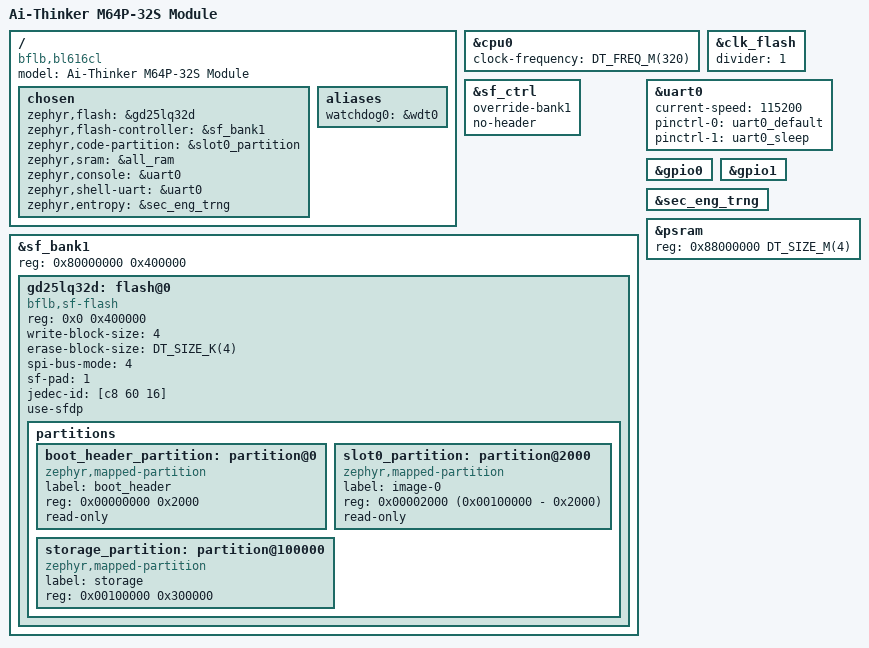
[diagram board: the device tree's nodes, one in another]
/*
 * Copyright (c) 2026 MASSDRIVER EI (massdriver.space)
 *
 * SPDX-License-Identifier: Apache-2.0
 */

#include <bflb/bl616cl.dtsi>
#include "ai_m64p_32s-pinctrl.dtsi"

/ {
	model = "Ai-Thinker M64P-32S Module";
	compatible = "bflb,bl616cl";

	chosen {
		zephyr,flash = &gd25lq32d;
		zephyr,flash-controller = &sf_bank1;
		zephyr,code-partition = &slot0_partition;
		zephyr,sram = &all_ram;
		zephyr,console = &uart0;
		zephyr,shell-uart = &uart0;
		zephyr,entropy = &sec_eng_trng;
	};

	aliases {
		watchdog0 = &wdt0;
	};
};

&cpu0 {
	clock-frequency = <DT_FREQ_M(320)>;
};

&clk_flash {
	divider = <1>;
};

&sf_ctrl {
	override-bank1;
	no-header;
};

&sf_bank1 {
	reg = <0x80000000 0x400000>;
	ranges = <0x0 0x80000000 0x400000>;

	gd25lq32d: flash@0 {
		compatible = "bflb,sf-flash", "soc-nv-flash";
		reg = <0x0 0x400000>;
		ranges;
		#address-cells = <1>;
		#size-cells = <1>;
		write-block-size = <4>;
		erase-block-size = <DT_SIZE_K(4)>;

		spi-bus-mode = <4>;
		sf-pad = <1>;
		jedec-id = [c8 60 16];
		use-sfdp;

		partitions {
			ranges;
			#address-cells = <1>;
			#size-cells = <1>;

			boot_header_partition: partition@0 {
				compatible = "zephyr,mapped-partition";
				label = "boot_header";
				reg = <0x00000000 0x2000>;
				read-only;
			};

			slot0_partition: partition@2000 {
				compatible = "zephyr,mapped-partition";
				label = "image-0";
				reg = <0x00002000 (0x00100000 - 0x2000)>;
				read-only;
			};

			storage_partition: partition@100000 {
				compatible = "zephyr,mapped-partition";
				label = "storage";
				reg = <0x00100000 0x300000>;
			};
		};
	};
};

&uart0 {
	status = "okay";
	current-speed = <115200>;

	pinctrl-0 = <&uart0_default>;
	pinctrl-1 = <&uart0_sleep>;
	pinctrl-names = "default", "sleep";
};

&gpio0 {
	status = "okay";
};

&gpio1 {
	status = "okay";
};

&sec_eng_trng {
	status = "okay";
};

&psram {
	status = "okay";
	reg = <0x88000000 DT_SIZE_M(4)>;
	ranges = <0x0 0x88000000 DT_SIZE_M(4)>;
};
